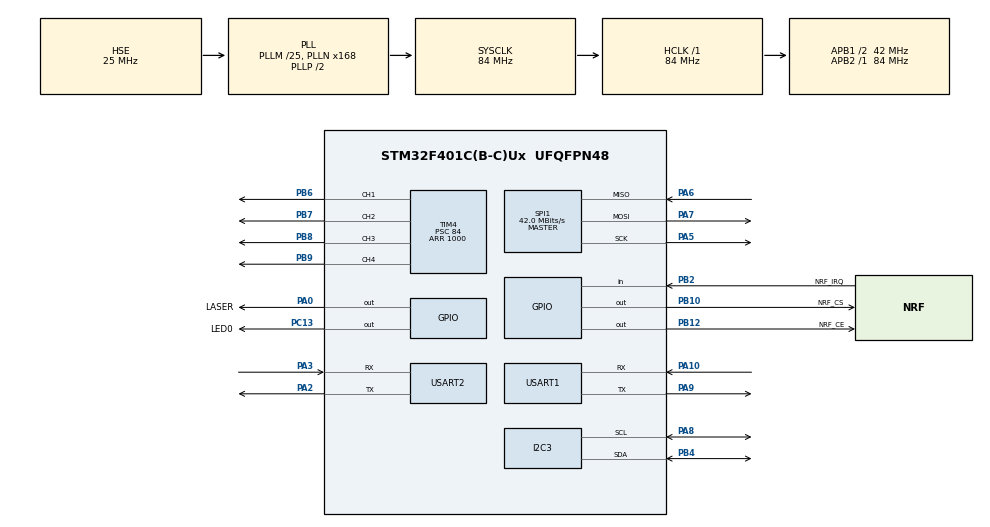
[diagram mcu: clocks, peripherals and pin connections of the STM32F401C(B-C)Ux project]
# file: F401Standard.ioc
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Dma.Request0=USART1_TX
Dma.Request1=USART1_RX
Dma.Request2=SPI1_TX
Dma.SPI1_TX.2.Direction=DMA_MEMORY_TO_PERIPH
Dma.SPI1_TX.2.FIFOMode=DMA_FIFOMODE_DISABLE
Dma.SPI1_TX.2.Instance=DMA2_Stream5
Dma.SPI1_TX.2.MemDataAlignment=DMA_MDATAALIGN_BYTE
Dma.SPI1_TX.2.MemInc=DMA_MINC_DISABLE
Dma.SPI1_TX.2.Mode=DMA_NORMAL
Dma.SPI1_TX.2.PeriphDataAlignment=DMA_PDATAALIGN_BYTE
Dma.SPI1_TX.2.PeriphInc=DMA_PINC_DISABLE
Dma.SPI1_TX.2.Priority=DMA_PRIORITY_LOW
Dma.USART1_RX.1.Direction=DMA_PERIPH_TO_MEMORY
Dma.USART1_RX.1.FIFOMode=DMA_FIFOMODE_DISABLE
Dma.USART1_RX.1.Instance=DMA2_Stream2
Dma.USART1_RX.1.MemDataAlignment=DMA_MDATAALIGN_BYTE
Dma.USART1_RX.1.MemInc=DMA_MINC_ENABLE
Dma.USART1_RX.1.Mode=DMA_NORMAL
Dma.USART1_RX.1.PeriphDataAlignment=DMA_PDATAALIGN_BYTE
Dma.USART1_RX.1.PeriphInc=DMA_PINC_DISABLE
Dma.USART1_RX.1.Priority=DMA_PRIORITY_LOW
Dma.USART1_TX.0.Direction=DMA_MEMORY_TO_PERIPH
Dma.USART1_TX.0.FIFOMode=DMA_FIFOMODE_DISABLE
Dma.USART1_TX.0.Instance=DMA2_Stream7
Dma.USART1_TX.0.MemDataAlignment=DMA_MDATAALIGN_BYTE
Dma.USART1_TX.0.MemInc=DMA_MINC_ENABLE
Dma.USART1_TX.0.Mode=DMA_NORMAL
Dma.USART1_TX.0.PeriphDataAlignment=DMA_PDATAALIGN_BYTE
Dma.USART1_TX.0.PeriphInc=DMA_PINC_DISABLE
Dma.USART1_TX.0.Priority=DMA_PRIORITY_LOW
Mcu.Family=STM32F4
Mcu.Name=STM32F401C(B-C)Ux
Mcu.Package=UFQFPN48
NVIC.DMA2_Stream2_IRQn=true\:0\:0\:false\:false\:false\:false\:true
NVIC.DMA2_Stream5_IRQn=true\:0\:0\:false\:false\:false\:false\:true
NVIC.DMA2_Stream7_IRQn=true\:0\:0\:false\:false\:false\:false\:true
NVIC.PriorityGroup=NVIC_PRIORITYGROUP_4
NVIC.USART1_IRQn=true\:0\:0\:false\:false\:false\:true\:true
NVIC.USART2_IRQn=true\:0\:0\:false\:false\:false\:true\:true
PA0-WKUP.GPIO_Label=LASER
PA0-WKUP.Signal=GPIO_Output
PA10.Mode=Asynchronous
PA10.Signal=USART1_RX
PA13.Mode=Serial_Wire
PA13.Signal=SYS_JTMS-SWDIO
PA14.Mode=Serial_Wire
PA14.Signal=SYS_JTCK-SWCLK
PA2.Mode=Asynchronous
PA2.Signal=USART2_TX
PA3.Mode=Asynchronous
PA3.Signal=USART2_RX
PA5.Mode=Full_Duplex_Master
PA5.Signal=SPI1_SCK
PA6.Mode=Full_Duplex_Master
PA6.Signal=SPI1_MISO
PA7.Mode=Full_Duplex_Master
PA7.Signal=SPI1_MOSI
PA8.Mode=I2C
PA8.Signal=I2C3_SCL
PA9.Mode=Asynchronous
PA9.Signal=USART1_TX
PB10.GPIO_Label=NRF_CS
PB10.Signal=GPIO_Output
PB12.GPIO_Label=NRF_CE
PB12.Signal=GPIO_Output
PB2.GPIO_Label=NRF_IRQ
PB2.GPIO_PuPd=GPIO_PULLDOWN
PB2.Signal=GPIO_Input
PB4.Mode=I2C
PB4.Signal=I2C3_SDA
PB6.Signal=S_TIM4_CH1
PB7.Signal=S_TIM4_CH2
PB8.Signal=S_TIM4_CH3
PB9.Signal=S_TIM4_CH4
PC13-ANTI_TAMP.GPIO_Label=LED0
PC13-ANTI_TAMP.Signal=GPIO_Output
PC14-OSC32_IN.Mode=LSE-External-Oscillator
PC14-OSC32_IN.Signal=RCC_OSC32_IN
PC15-OSC32_OUT.Mode=LSE-External-Oscillator
PC15-OSC32_OUT.Signal=RCC_OSC32_OUT
PH0\ -\ OSC_IN.Mode=HSE-External-Oscillator
PH0\ -\ OSC_IN.Signal=RCC_OSC_IN
PH1\ -\ OSC_OUT.Mode=HSE-External-Oscillator
PH1\ -\ OSC_OUT.Signal=RCC_OSC_OUT
ProjectManager.HeapSize=0x200
ProjectManager.StackSize=0x400
ProjectManager.TargetToolchain=MDK-ARM V5
RCC.48MHZClocksFreq_Value=42000000
RCC.AHBFreq_Value=84000000
RCC.APB1CLKDivider=RCC_HCLK_DIV2
RCC.APB1Freq_Value=42000000
RCC.APB1TimFreq_Value=84000000
RCC.APB2Freq_Value=84000000
RCC.APB2TimFreq_Value=84000000
RCC.CortexFreq_Value=84000000
RCC.HCLKFreq_Value=84000000
RCC.HSE_VALUE=25000000
RCC.HSI_VALUE=16000000
RCC.PLLM=25
RCC.PLLN=168
RCC.PLLSourceVirtual=RCC_PLLSOURCE_HSE
RCC.SYSCLKFreq_VALUE=84000000
RCC.SYSCLKSource=RCC_SYSCLKSOURCE_PLLCLK
RCC.VCOOutputFreq_Value=168000000
SH.S_TIM4_CH1.0=TIM4_CH1,PWM Generation1 CH1
SH.S_TIM4_CH2.0=TIM4_CH2,PWM Generation2 CH2
SH.S_TIM4_CH3.0=TIM4_CH3,PWM Generation3 CH3
SH.S_TIM4_CH4.0=TIM4_CH4,PWM Generation4 CH4
SPI1.BaudRatePrescaler=SPI_BAUDRATEPRESCALER_2
SPI1.CLKPhase=SPI_PHASE_2EDGE
SPI1.CLKPolarity=SPI_POLARITY_HIGH
SPI1.CalculateBaudRate=42.0 MBits/s
SPI1.Direction=SPI_DIRECTION_2LINES
SPI1.Mode=SPI_MODE_MASTER
SPI1.VirtualType=VM_MASTER
TIM4.Channel-PWM\ Generation1\ CH1=TIM_CHANNEL_1
TIM4.Channel-PWM\ Generation2\ CH2=TIM_CHANNEL_2
TIM4.Channel-PWM\ Generation3\ CH3=TIM_CHANNEL_3
TIM4.Channel-PWM\ Generation4\ CH4=TIM_CHANNEL_4
TIM4.Period=1000
TIM4.Prescaler=84
USART1.VirtualMode=VM_ASYNC
USART2.VirtualMode=VM_ASYNC
board=custom

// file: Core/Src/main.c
/* USER CODE BEGIN Header */
/**
  ******************************************************************************
  * @file           : main.c
  * @brief          : Main program body
  ******************************************************************************
  * @attention
  *
  * <h2><center>&copy; Copyright (c) 2021 STMicroelectronics.
  * All rights reserved.</center></h2>
  *
  * This software component is licensed by ST under BSD 3-Clause license,
  * the "License"; You may not use this file except in compliance with the
  * License. You may obtain a copy of the License at:
  *                        opensource.org/licenses/BSD-3-Clause
  *
  ******************************************************************************
  */
/* USER CODE END Header */
#include "main.h"
#include "dma.h"
#include "i2c.h"
#include "spi.h"
#include "tim.h"
#include "usart.h"
#include "gpio.h"

/* USER CODE BEGIN Includes */
#include "appMain.h"
#include "motorcol.h"
/* USER CODE END Includes */

void SystemClock_Config(void);

/* USER CODE BEGIN 0 */

uint32_t appcount = 0;//systick计时

/* USER CODE END 0 */

int main(void)
{

  /* MCU Configuration--------------------------------------------------------*/

  /* Reset of all peripherals, Initializes the Flash interface and the Systick. */
  HAL_Init();

  /* Configure the system clock */
  SystemClock_Config();

  /* Initialize all configured peripherals */
  MX_GPIO_Init();
  MX_DMA_Init();
  MX_USART1_UART_Init();
  MX_SPI1_Init();
  MX_I2C3_Init();
  MX_TIM4_Init();
  MX_USART2_UART_Init();
  /* USER CODE BEGIN 2 */
	appInit();

  /* USER CODE END 2 */

  /* Infinite loop */
  while (1)
  {

    /* USER CODE BEGIN 3 */

	  appMain();
  }
  /* USER CODE END 3 */
}

void SystemClock_Config(void)
{
  RCC_OscInitTypeDef RCC_OscInitStruct = {0};
  RCC_ClkInitTypeDef RCC_ClkInitStruct = {0};

  /** Configure the main internal regulator output voltage
  */
  __HAL_RCC_PWR_CLK_ENABLE();
  __HAL_PWR_VOLTAGESCALING_CONFIG(PWR_REGULATOR_VOLTAGE_SCALE2);
  /** Initializes the RCC Oscillators according to the specified parameters
  * in the RCC_OscInitTypeDef structure.
  */
  RCC_OscInitStruct.OscillatorType = RCC_OSCILLATORTYPE_HSE;
  RCC_OscInitStruct.HSEState = RCC_HSE_ON;
  RCC_OscInitStruct.PLL.PLLState = RCC_PLL_ON;
  RCC_OscInitStruct.PLL.PLLSource = RCC_PLLSOURCE_HSE;
  RCC_OscInitStruct.PLL.PLLM = 25;
  RCC_OscInitStruct.PLL.PLLN = 168;
  RCC_OscInitStruct.PLL.PLLP = RCC_PLLP_DIV2;
  RCC_OscInitStruct.PLL.PLLQ = 4;
  if (HAL_RCC_OscConfig(&RCC_OscInitStruct) != HAL_OK)
  {
    Error_Handler();
  }
  /** Initializes the CPU, AHB and APB buses clocks
  */
  RCC_ClkInitStruct.ClockType = RCC_CLOCKTYPE_HCLK|RCC_CLOCKTYPE_SYSCLK
                              |RCC_CLOCKTYPE_PCLK1|RCC_CLOCKTYPE_PCLK2;
  RCC_ClkInitStruct.SYSCLKSource = RCC_SYSCLKSOURCE_PLLCLK;
  RCC_ClkInitStruct.AHBCLKDivider = RCC_SYSCLK_DIV1;
  RCC_ClkInitStruct.APB1CLKDivider = RCC_HCLK_DIV2;
  RCC_ClkInitStruct.APB2CLKDivider = RCC_HCLK_DIV1;

  if (HAL_RCC_ClockConfig(&RCC_ClkInitStruct, FLASH_LATENCY_2) != HAL_OK)
  {
    Error_Handler();
  }
}

void Error_Handler(void)
{
  __disable_irq();
  while (1)
  {
  }
}

/************************ (C) COPYRIGHT STMicroelectronics *****END OF FILE****/
